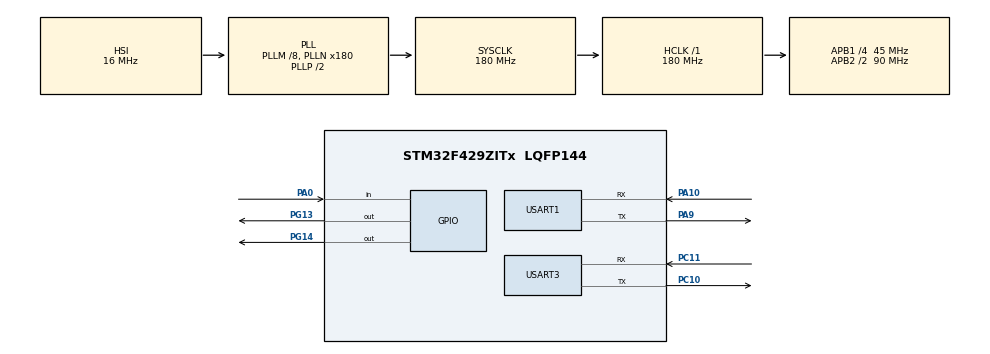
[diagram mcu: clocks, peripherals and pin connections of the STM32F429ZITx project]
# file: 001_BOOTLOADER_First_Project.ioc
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Mcu.Family=STM32F4
Mcu.Name=STM32F429ZITx
Mcu.Package=LQFP144
NVIC.PriorityGroup=NVIC_PRIORITYGROUP_0
PA0/WKUP.GPIO_PuPd=GPIO_PULLDOWN
PA0/WKUP.Signal=GPIO_Input
PA10.Mode=Asynchronous
PA10.Signal=USART1_RX
PA9.Mode=Asynchronous
PA9.Signal=USART1_TX
PC10.Mode=Asynchronous
PC10.Signal=USART3_TX
PC11.Mode=Asynchronous
PC11.Signal=USART3_RX
PG13.Signal=GPIO_Output
PG14.Signal=GPIO_Output
ProjectManager.HeapSize=0x200
ProjectManager.StackSize=0x400
ProjectManager.TargetToolchain=TrueSTUDIO
RCC.48MHZClocksFreq_Value=51428571.428571425
RCC.AHBFreq_Value=180000000
RCC.APB1CLKDivider=RCC_HCLK_DIV4
RCC.APB1Freq_Value=45000000
RCC.APB1TimFreq_Value=90000000
RCC.APB2CLKDivider=RCC_HCLK_DIV2
RCC.APB2Freq_Value=90000000
RCC.APB2TimFreq_Value=180000000
RCC.CortexFreq_Value=180000000
RCC.HCLKFreq_Value=180000000
RCC.HSE_VALUE=8000000
RCC.HSI_VALUE=16000000
RCC.LSE_VALUE=32768
RCC.PLLM=8
RCC.PLLN=180
RCC.PLLQ=7
RCC.SYSCLKFreq_VALUE=180000000
RCC.SYSCLKSource=RCC_SYSCLKSOURCE_PLLCLK
RCC.VCOOutputFreq_Value=360000000
USART1.VirtualMode=VM_ASYNC
USART3.VirtualMode=VM_ASYNC
VP_CRC_VS_CRC.Mode=CRC_Activate
board=STM32F429I-DISC1

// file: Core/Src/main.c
/* USER CODE BEGIN Header */
/**
  ******************************************************************************
  * @file           : main.c
  * @brief          : Main program body
  ******************************************************************************
  * @attention
  *
  * Copyright (c) 2023 STMicroelectronics.
  * All rights reserved.
  *
  * This software is licensed under terms that can be found in the LICENSE file
  * in the root directory of this software component.
  * If no LICENSE file comes with this software, it is provided AS-IS.
  *
  ******************************************************************************
  */
/* USER CODE END Header */
#include "main.h"

/* USER CODE BEGIN Includes */
#include "string.h"
#include "stdio.h"
#include "stdarg.h"
/* USER CODE END Includes */

/* USER CODE BEGIN PD */
#define DEBUG_UART &huart3
/* USER CODE END PD */

/* USER CODE BEGIN PM */
void printMsg(char *msg,...);
/* USER CODE END PM */

 CRC_HandleTypeDef hcrc;

UART_HandleTypeDef huart1;
UART_HandleTypeDef huart3;

void SystemClock_Config(void);
static void MX_GPIO_Init(void);
static void MX_USART1_UART_Init(void);
static void MX_USART3_UART_Init(void);
static void MX_CRC_Init(void);

int main(void)
{

  /* MCU Configuration--------------------------------------------------------*/

  /* Reset of all peripherals, Initializes the Flash interface and the Systick. */
  HAL_Init();

  /* Configure the system clock */
  SystemClock_Config();

  /* Initialize all configured peripherals */
  MX_GPIO_Init();
  MX_USART1_UART_Init();
  MX_USART3_UART_Init();
  MX_CRC_Init();

  /* Infinite loop */
  while (1)
  {

    /* USER CODE BEGIN 3 */
	printMsg("Hello from the Bootloader %d. Project\r\n",1);
	HAL_Delay(1000);
  }
  /* USER CODE END 3 */
}

void SystemClock_Config(void)
{
  RCC_OscInitTypeDef RCC_OscInitStruct = {0};
  RCC_ClkInitTypeDef RCC_ClkInitStruct = {0};

  /** Configure the main internal regulator output voltage
  */
  __HAL_RCC_PWR_CLK_ENABLE();
  __HAL_PWR_VOLTAGESCALING_CONFIG(PWR_REGULATOR_VOLTAGE_SCALE1);

  /** Initializes the RCC Oscillators according to the specified parameters
  * in the RCC_OscInitTypeDef structure.
  */
  RCC_OscInitStruct.OscillatorType = RCC_OSCILLATORTYPE_HSI;
  RCC_OscInitStruct.HSIState = RCC_HSI_ON;
  RCC_OscInitStruct.HSICalibrationValue = RCC_HSICALIBRATION_DEFAULT;
  RCC_OscInitStruct.PLL.PLLState = RCC_PLL_ON;
  RCC_OscInitStruct.PLL.PLLSource = RCC_PLLSOURCE_HSI;
  RCC_OscInitStruct.PLL.PLLM = 8;
  RCC_OscInitStruct.PLL.PLLN = 180;
  RCC_OscInitStruct.PLL.PLLP = RCC_PLLP_DIV2;
  RCC_OscInitStruct.PLL.PLLQ = 7;
  if (HAL_RCC_OscConfig(&RCC_OscInitStruct) != HAL_OK)
  {
    Error_Handler();
  }

  /** Activate the Over-Drive mode
  */
  if (HAL_PWREx_EnableOverDrive() != HAL_OK)
  {
    Error_Handler();
  }

  /** Initializes the CPU, AHB and APB buses clocks
  */
  RCC_ClkInitStruct.ClockType = RCC_CLOCKTYPE_HCLK|RCC_CLOCKTYPE_SYSCLK
                              |RCC_CLOCKTYPE_PCLK1|RCC_CLOCKTYPE_PCLK2;
  RCC_ClkInitStruct.SYSCLKSource = RCC_SYSCLKSOURCE_PLLCLK;
  RCC_ClkInitStruct.AHBCLKDivider = RCC_SYSCLK_DIV1;
  RCC_ClkInitStruct.APB1CLKDivider = RCC_HCLK_DIV4;
  RCC_ClkInitStruct.APB2CLKDivider = RCC_HCLK_DIV2;

  if (HAL_RCC_ClockConfig(&RCC_ClkInitStruct, FLASH_LATENCY_5) != HAL_OK)
  {
    Error_Handler();
  }
}

static void MX_CRC_Init(void)
{

  hcrc.Instance = CRC;
  if (HAL_CRC_Init(&hcrc) != HAL_OK)
  {
    Error_Handler();
  }

}

static void MX_USART1_UART_Init(void)
{

  huart1.Instance = USART1;
  huart1.Init.BaudRate = 115200;
  huart1.Init.WordLength = UART_WORDLENGTH_8B;
  huart1.Init.StopBits = UART_STOPBITS_1;
  huart1.Init.Parity = UART_PARITY_NONE;
  huart1.Init.Mode = UART_MODE_TX_RX;
  huart1.Init.HwFlowCtl = UART_HWCONTROL_NONE;
  huart1.Init.OverSampling = UART_OVERSAMPLING_16;
  if (HAL_UART_Init(&huart1) != HAL_OK)
  {
    Error_Handler();
  }

}

static void MX_USART3_UART_Init(void)
{

  huart3.Instance = USART3;
  huart3.Init.BaudRate = 115200;
  huart3.Init.WordLength = UART_WORDLENGTH_8B;
  huart3.Init.StopBits = UART_STOPBITS_1;
  huart3.Init.Parity = UART_PARITY_NONE;
  huart3.Init.Mode = UART_MODE_TX_RX;
  huart3.Init.HwFlowCtl = UART_HWCONTROL_NONE;
  huart3.Init.OverSampling = UART_OVERSAMPLING_16;
  if (HAL_UART_Init(&huart3) != HAL_OK)
  {
    Error_Handler();
  }

}

static void MX_GPIO_Init(void)
{
  GPIO_InitTypeDef GPIO_InitStruct = {0};

  /* GPIO Ports Clock Enable */
  __HAL_RCC_GPIOA_CLK_ENABLE();
  __HAL_RCC_GPIOC_CLK_ENABLE();
  __HAL_RCC_GPIOG_CLK_ENABLE();

  /*Configure GPIO pin Output Level */
  HAL_GPIO_WritePin(GPIOG, GPIO_PIN_13|GPIO_PIN_14, GPIO_PIN_RESET);

  /*Configure GPIO pin : PA0 */
  GPIO_InitStruct.Pin = GPIO_PIN_0;
  GPIO_InitStruct.Mode = GPIO_MODE_INPUT;
  GPIO_InitStruct.Pull = GPIO_PULLDOWN;
  HAL_GPIO_Init(GPIOA, &GPIO_InitStruct);

  /*Configure GPIO pins : PG13 PG14 */
  GPIO_InitStruct.Pin = GPIO_PIN_13|GPIO_PIN_14;
  GPIO_InitStruct.Mode = GPIO_MODE_OUTPUT_PP;
  GPIO_InitStruct.Pull = GPIO_NOPULL;
  GPIO_InitStruct.Speed = GPIO_SPEED_FREQ_LOW;
  HAL_GPIO_Init(GPIOG, &GPIO_InitStruct);

}

/* USER CODE BEGIN 4 */
void printMsg(char *msg,...)
{
   char comingMsg[100];

  va_list vaList;
  va_start(vaList,msg);
  vsprintf(comingMsg,msg,vaList);
  HAL_UART_Transmit(DEBUG_UART,(uint8_t *)comingMsg,strlen(comingMsg),HAL_MAX_DELAY);
  va_end(vaList);

}
/* USER CODE END 4 */

void Error_Handler(void)
{
  __disable_irq();
  while (1)
  {
  }
}
